# PY32F040xx register map
Vendor: Puya; Series: PY32F0; File version: 1.0.0
CPU: CM0+ r0p1, little endian, no MPU, no FPU, 4 interrupt priority bits
Registers are 32-bit, read-write, reset 0x0 unless marked. A register's access mark holds for its fields unless they carry their own. Offsets are from the block's base; [hi:lo] are bit positions.

## I2C1 — Inter integrated circuit
Base 0x40005400
Same registers: I2C2 0x40005800
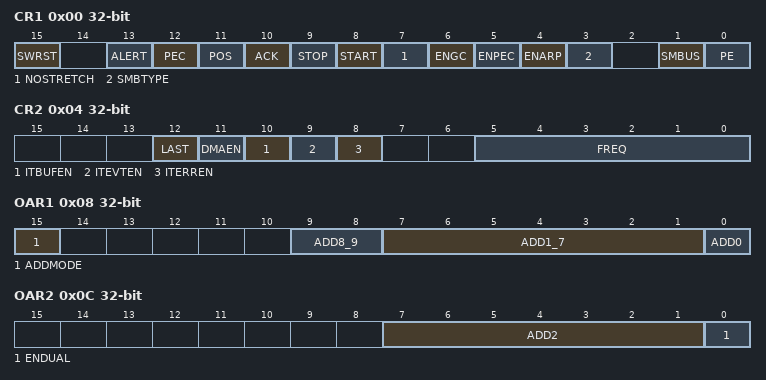
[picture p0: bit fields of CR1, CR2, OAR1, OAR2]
0x00 CR1
  [15] SWRST
    0=NotReset (I2C peripheral not under reset); 1=Reset (I2C peripheral under reset)
  [13] ALERT
    0=Release the SMBAlert pin to make it high; 1=Drive the SMBAlert pin to make it low
  [12] PEC
    0=NoErrorCheck (no Packet error correction transmission); 1=ErrorCheckOn (Packet error correction transmission)
  [11] POS
    0=Current (ACK bit controls the (N)ACK of the current byte being received); 1=Next (ACK bit controls the (N)ACK of the next byte to be received)
  [10] ACK
    0=NAK (No acknowledge returned); 1=ACK (Acknowledge returned after a byte is received)
  [9] STOP
    0=No Stop generation; 1=Stop (In master mode: stop generation after current byte/start, in slave mode: release SCL and SDA after current byte)
  [8] START
    0=No Start generation; 1=Start (In master mode: repeated start generation, in slave mode: start generation when bus is free)
  [7] NOSTRETCH
    0=Enabled (Clock stretching enabled); 1=Disabled (Clock stretching disabled)
  [6] ENGC
    0=Disabled (General call disabled); 1=Enabled (General call enabled)
  [5] ENPEC
    0=Disabled (PEC calculation disabled); 1=Enabled (PEC calculation enabled)
  [4] ENARP
    0=Disabled (ARP disabled); 1=Enabled (ARP enabled)
  [3] SMBTYPE
    0=Device (SMB device); 1=Host (SMB host)
  [1] SMBUS
    0=I2c (I2c mode); 1=SMBus mode
  [0] PE
    0=Disabled (Peripheral disabled); 1=Enabled (Peripheral enabled)
0x04 CR2
  [12] LAST
    0=NotLast (Next DMA EOT is not the last transfer); 1=Last (Next DMA EOT is the last transfer)
  [11] DMAEN
    0=Disabled (DMA requests disabled); 1=Enabled (DMA request enabled when TxE=1 or RxNE=1)
  [10] ITBUFEN
    0=Disabled (TxE=1 or RxNE=1 does not generate any interrupt); 1=Enabled (TxE=1 or RxNE=1 generates Event interrupt)
  [9] ITEVTEN
    0=Disabled (Event interrupt disabled); 1=Enabled (Event interrupt enabled)
  [8] ITERREN
    0=Disabled (Error interrupt disabled); 1=Enabled (Error interrupt enabled)
  [5:0] FREQ range 4..50
0x08 OAR1
  [15] ADDMODE
    0=SevenBit (7-bit slave address (does not respond to a 10-bit address)); 1=TenBit (10-bit slave address (does not respond to a 7-bit address))
  [9:8] ADD8_9
  [7:1] ADD1_7
  [0] ADD0
0x0C OAR2
  [7:1] ADD2
  [0] ENDUAL
    0=Disabled (in 7-bit adddress mode, only OAR1 is recognized); 1=Enabled (in 7-bit adddress mode, both OAR1 and OAR2 are recognized)
0x10 DR
  [7:0] DR
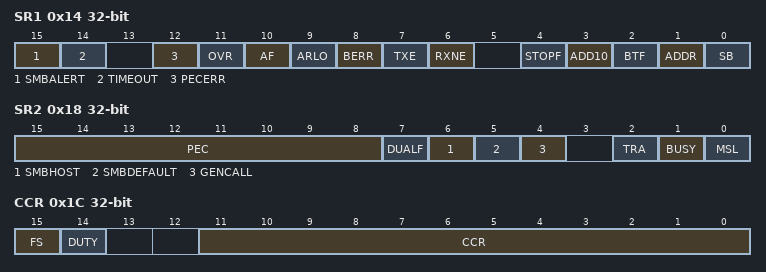
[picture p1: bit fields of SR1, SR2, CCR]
0x14 SR1
  [15] SMBALERT write-0-clears
    on read: 0=NoAlert (No SMBAlert); 1=Alert (SMBAlert Event) | on write: 0=Clear flag
  [14] TIMEOUT write-0-clears
    on read: 0=No timeout error; 1=Timeout | on write: 0=Clear flag
  [12] PECERR write-0-clears
    on read: 0=NoError (no PEC error: receiver returns ACK after PEC reception (if ACK=1)); 1=Error (PEC error: receiver returns NACK after PEC reception (whatever ACK)) | on write: 0=Clear flag
  [11] OVR write-0-clears
    on read: 0=No overrun/underrun occured; 1=Overrun/underrun occured | on write: 0=Clear flag
  [10] AF write-0-clears
    on read: 0=NoFailure (No acknowledge failure); 1=Failure (Acknowledge failure) | on write: 0=Clear flag
  [9] ARLO write-0-clears
    on read: 0=NoLost (No Arbitration Lost detected); 1=Lost (Arbitration Lost detected) | on write: 0=Clear flag
  [8] BERR write-0-clears
    on read: 0=NoError (No misplaced Start or Stop condition); 1=Error (Misplaced Start or Stop condition) | on write: 0=Clear flag
  [7] TXE ro
    0=NotEmpty (Data register not empty); 1=Empty (Data register empty)
  [6] RXNE ro
    0=Empty (Data register empty); 1=NotEmpty (Data register not empty)
  [4] STOPF ro
    0=No Stop condition detected; 1=Stop condition detected
  [3] ADD10 ro
    0=NoEvent (No ADD10 event occurred); 1=Sent (Master device has sent the first address out)
  [2] BTF ro
    0=NotFinished (Data byte transfer not done); 1=Finished (Data byte transfer successful)
  [1] ADDR ro
    0=NoMatch (Address does not match); 1=Match (Address matched)
  [0] SB ro
    0=No Start condition; 1=Start condition generated
0x18 SR2 ro
  [15:8] PEC range 0..1
  [7] DUALF
    0=Oar1 (Received address matches OAR1); 1=Oar2 (Received address matches OAR2)
  [6] SMBHOST
    0=NotRecv (SMBus host address not received); 1=Recv (SMBus host address received)
  [5] SMBDEFAULT
    0=NoDefault (Default address of SMBus device not received); 1=Default address of SMBus device received
  [4] GENCALL
    0=NoGeneralCallRecv (Not receive general call address); 1=GeneralCallRecv (When ENGC=1, received a general call address)
  [2] TRA
    0=Received (Data received flag); 1=Transferred (Data transferred flag)
  [1] BUSY
    0=NotBusy (No communication on bus); 1=Busy (Bus busy)
  [0] MSL
    0=Slave mode; 1=Master mode
0x1C CCR
  [15] FS
    0=Standard mode I2C; 1=Fast mode I2C
  [14] DUTY
    0=Duty2_1 (Duty cycle t_low/t_high = 2/1); 1=Duty16_9 (Duty cycle t_low/t_high = 16/9)
  [11:0] CCR range 1..4095
0x20 TRISE reset 0x2
  [5:0] TRISE
